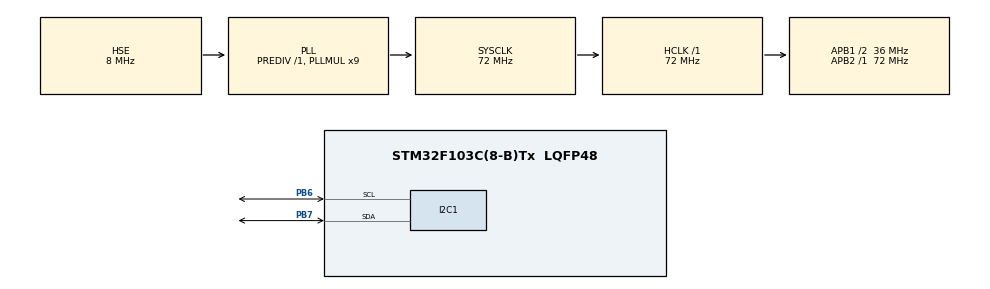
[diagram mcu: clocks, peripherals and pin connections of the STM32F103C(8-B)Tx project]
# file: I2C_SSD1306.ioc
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I2C1.I2C_Mode=I2C_Fast
Mcu.Family=STM32F1
Mcu.Name=STM32F103C(8-B)Tx
Mcu.Package=LQFP48
NVIC.PriorityGroup=NVIC_PRIORITYGROUP_4
PA13.Mode=Serial_Wire
PA13.Signal=SYS_JTMS-SWDIO
PA14.Mode=Serial_Wire
PA14.Signal=SYS_JTCK-SWCLK
PB6.Mode=I2C
PB6.Signal=I2C1_SCL
PB7.Mode=I2C
PB7.Signal=I2C1_SDA
PD0-OSC_IN.Mode=HSE-External-Oscillator
PD0-OSC_IN.Signal=RCC_OSC_IN
PD1-OSC_OUT.Mode=HSE-External-Oscillator
PD1-OSC_OUT.Signal=RCC_OSC_OUT
ProjectManager.HeapSize=0x200
ProjectManager.StackSize=0x400
ProjectManager.TargetToolchain=MDK-ARM V5.32
RCC.AHBFreq_Value=72000000
RCC.APB1CLKDivider=RCC_HCLK_DIV2
RCC.APB1Freq_Value=36000000
RCC.APB1TimFreq_Value=72000000
RCC.APB2Freq_Value=72000000
RCC.APB2TimFreq_Value=72000000
RCC.HCLKFreq_Value=72000000
RCC.PLLMUL=RCC_PLL_MUL9
RCC.PLLSourceVirtual=RCC_PLLSOURCE_HSE
RCC.SYSCLKFreq_VALUE=72000000
RCC.SYSCLKSource=RCC_SYSCLKSOURCE_PLLCLK
RCC.USBFreq_Value=72000000
board=custom

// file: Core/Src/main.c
/* USER CODE BEGIN Header */
/**
  ******************************************************************************
  * @file           : main.c
  * @brief          : Main program body
  ******************************************************************************
  * @attention
  *
  * Copyright (c) 2024 STMicroelectronics.
  * All rights reserved.
  *
  * This software is licensed under terms that can be found in the LICENSE file
  * in the root directory of this software component.
  * If no LICENSE file comes with this software, it is provided AS-IS.
  *
  ******************************************************************************
  */
/* USER CODE END Header */
#include "main.h"

/* USER CODE BEGIN Includes */
#include "fonts.h"
#include "ssd1306.h"
/* USER CODE END Includes */

I2C_HandleTypeDef hi2c1;

void SystemClock_Config(void);
static void MX_GPIO_Init(void);
static void MX_I2C1_Init(void);

/* USER CODE BEGIN 0 */
// 'icons8-calendar-22', 22x22px
const unsigned char epd_bitmap_icons8_calendar_22 [] = {
	0xf9, 0xfe, 0x7c, 0xf5, 0xfe, 0xbc, 0x84, 0x00, 0x84, 0x80, 0x00, 0x04, 0x80, 0x00, 0x04, 0x80,
	0x00, 0x04, 0xff, 0xff, 0xfc, 0x80, 0x00, 0x04, 0x80, 0x00, 0x04, 0x86, 0x49, 0x84, 0x86, 0xfd,
	0x84, 0x80, 0x00, 0x04, 0x82, 0x49, 0x04, 0x86, 0xfd, 0x84, 0x82, 0x49, 0x04, 0x82, 0x49, 0x04,
	0x86, 0xfd, 0x84, 0x82, 0x49, 0x04, 0x80, 0x00, 0x04, 0x80, 0x00, 0x04, 0x80, 0x00, 0x04, 0xff,
	0xff, 0xfc
};
// 'icons8-time-20', 20x20px
// 'icons8-time-20 (1)', 20x20px
const unsigned char epd_bitmap_icons8_time_20__1_ []= {
	0xff, 0xff, 0xf0, 0xff, 0xff, 0xf0, 0xff, 0x0f, 0xf0, 0xff, 0x9f, 0xf0, 0xfe, 0x07, 0xf0, 0xfc,
	0x01, 0xf0, 0xf8, 0x01, 0xf0, 0xf1, 0x00, 0xf0, 0xf1, 0x80, 0xf0, 0xe0, 0xc0, 0x70, 0xe0, 0x60,
	0x70, 0xe0, 0x20, 0x70, 0xf0, 0x00, 0xf0, 0xf0, 0x00, 0xf0, 0xf8, 0x01, 0xf0, 0xfc, 0x03, 0xf0,
	0xfe, 0x07, 0xf0, 0xff, 0xff, 0xf0, 0xff, 0xff, 0xf0, 0xff, 0xff, 0xf0
};
// 'icons8-high-temperatures-64', 64x64px
const unsigned char epd_bitmap_icons8_high_temperatures_64 []  = {
	0x00, 0x00, 0x00, 0x00, 0x00, 0x00, 0x00, 0x00, 0x00, 0x00, 0x00, 0x03, 0xc0, 0x00, 0x00, 0x00,
	0x00, 0x00, 0x00, 0x0f, 0xf0, 0x00, 0x00, 0x00, 0x00, 0x00, 0x00, 0x1f, 0xf8, 0x00, 0x00, 0x00,
	0x00, 0x00, 0x00, 0x1f, 0xf8, 0x00, 0x00, 0x00, 0x00, 0x00, 0x00, 0x3f, 0xfc, 0x00, 0x00, 0x00,
	0x00, 0x00, 0x00, 0x3e, 0x7c, 0x00, 0x00, 0x00, 0x00, 0x00, 0x00, 0x3c, 0x3c, 0x00, 0x00, 0x00,
	0x00, 0x00, 0x00, 0x3c, 0x3c, 0x00, 0x00, 0x00, 0x00, 0x00, 0x1f, 0xfc, 0x3f, 0xf8, 0x00, 0x00,
	0x00, 0x00, 0x1f, 0xfc, 0x3f, 0xf8, 0x00, 0x00, 0x00, 0x00, 0x00, 0x3c, 0x3c, 0x00, 0x00, 0x00,
	0x00, 0x00, 0x00, 0x3c, 0x3c, 0x00, 0x00, 0x00, 0x00, 0x00, 0x00, 0x3c, 0x3c, 0x00, 0x00, 0x00,
	0x00, 0x00, 0x00, 0x3c, 0x3c, 0x00, 0x00, 0x00, 0x00, 0x00, 0x07, 0xfc, 0x3f, 0xe0, 0x00, 0x00,
	0x00, 0x00, 0x07, 0xfc, 0x3f, 0xe0, 0x00, 0x00, 0x00, 0x00, 0x00, 0x3c, 0x3c, 0x00, 0x00, 0x00,
	0x00, 0x00, 0x00, 0x3c, 0x3c, 0x00, 0x00, 0x00, 0x00, 0x00, 0x00, 0x3c, 0x3c, 0x00, 0x00, 0x00,
	0x00, 0x00, 0x00, 0x3c, 0x3c, 0x00, 0x00, 0x00, 0x00, 0x00, 0x1f, 0xfc, 0x3f, 0xf8, 0x00, 0x00,
	0x00, 0x00, 0x1f, 0xfc, 0x3f, 0xf8, 0x00, 0x00, 0x00, 0x00, 0x00, 0x3c, 0x3c, 0x00, 0x00, 0x00,
	0x00, 0x00, 0x00, 0x3c, 0x3c, 0x00, 0x00, 0x00, 0x00, 0x00, 0x00, 0x3c, 0x3c, 0x00, 0x00, 0x00,
	0x00, 0x00, 0x00, 0x3c, 0x3c, 0x00, 0x00, 0x00, 0x00, 0x00, 0x07, 0xfc, 0x3f, 0xe0, 0x00, 0x00,
	0x00, 0x00, 0x07, 0xfc, 0x3f, 0xe0, 0x00, 0x00, 0x00, 0x00, 0x00, 0x3c, 0x3c, 0x00, 0x00, 0x00,
	0x00, 0x00, 0x00, 0x3c, 0x3c, 0x00, 0x00, 0x00, 0x00, 0x00, 0x00, 0x3c, 0x3c, 0x00, 0x00, 0x00,
	0x00, 0x00, 0x00, 0x3c, 0x3c, 0x00, 0x00, 0x00, 0x00, 0x00, 0x1f, 0xfc, 0x3f, 0xf8, 0x00, 0x00,
	0x00, 0x00, 0x1f, 0xfc, 0x3f, 0xf8, 0x00, 0x00, 0x00, 0x00, 0x00, 0x3c, 0x3c, 0x00, 0x00, 0x00,
	0x00, 0x00, 0x00, 0x3c, 0x3c, 0x00, 0x00, 0x00, 0x00, 0x00, 0x00, 0x3c, 0x3c, 0x00, 0x00, 0x00,
	0x00, 0x00, 0x00, 0x3c, 0x3c, 0x00, 0x00, 0x00, 0x00, 0x00, 0x07, 0xfc, 0x3f, 0xe0, 0x00, 0x00,
	0x00, 0x00, 0x07, 0xfc, 0x3f, 0xe0, 0x00, 0x00, 0x00, 0x00, 0x00, 0x3c, 0x3c, 0x00, 0x00, 0x00,
	0x00, 0x00, 0x00, 0x3c, 0x3c, 0x00, 0x00, 0x00, 0x00, 0x00, 0x00, 0x3c, 0x3c, 0x00, 0x00, 0x00,
	0x00, 0x00, 0x00, 0x3c, 0x3c, 0x00, 0x00, 0x00, 0x00, 0x00, 0x00, 0x7c, 0x3e, 0x00, 0x00, 0x00,
	0x00, 0x00, 0x00, 0xfc, 0x3f, 0x00, 0x00, 0x00, 0x00, 0x00, 0x00, 0xfc, 0x3f, 0x00, 0x00, 0x00,
	0x00, 0x30, 0x01, 0xfc, 0x3f, 0x80, 0x00, 0x00, 0x00, 0x30, 0x01, 0xf8, 0x1f, 0x80, 0x00, 0x00,
	0x00, 0x30, 0x03, 0xf0, 0x0f, 0xc0, 0x00, 0x00, 0x00, 0x30, 0x03, 0xe0, 0x07, 0xc0, 0x00, 0x00,
	0x03, 0xff, 0x03, 0xe0, 0x07, 0xc0, 0xff, 0xc0, 0x03, 0xff, 0x03, 0xe0, 0x07, 0xc0, 0xff, 0xc0,
	0x00, 0x30, 0x03, 0xe0, 0x07, 0xc0, 0x00, 0x00, 0x00, 0x30, 0x03, 0xf0, 0x0f, 0xc0, 0x00, 0x00,
	0x00, 0x30, 0x01, 0xf8, 0x1f, 0x80, 0x00, 0x00, 0x00, 0x30, 0x01, 0xfc, 0x3f, 0x80, 0x00, 0x00,
	0x00, 0x00, 0x00, 0xff, 0xff, 0x00, 0x00, 0x00, 0x00, 0x00, 0x00, 0xff, 0xff, 0x00, 0x00, 0x00,
	0x00, 0x00, 0x00, 0x7f, 0xfe, 0x00, 0x00, 0x00, 0x00, 0x00, 0x00, 0x1f, 0xf8, 0x00, 0x00, 0x00,
	0x00, 0x00, 0x00, 0x07, 0xe0, 0x00, 0x00, 0x00, 0x00, 0x00, 0x00, 0x00, 0x00, 0x00, 0x00, 0x00
};
// 'icons8-high-temperatures-20', 20x20px
const unsigned char epd_bitmap_icons8_high_temperatures_20 [] = {
	0x00, 0x60, 0x00, 0x00, 0xf0, 0x00, 0x00, 0x90, 0x00, 0x00, 0x90, 0x00, 0x00, 0x90, 0x00, 0x00,
	0x90, 0x00, 0x00, 0x90, 0x00, 0x00, 0x90, 0x00, 0x01, 0x98, 0x00, 0x00, 0x90, 0x00, 0x03, 0x9c,
	0x00, 0x00, 0x90, 0x00, 0x01, 0x98, 0x00, 0x00, 0x90, 0x00, 0x00, 0x90, 0x00, 0x11, 0x98, 0x00,
	0x39, 0x09, 0xc0, 0x11, 0x98, 0x00, 0x00, 0xf0, 0x00, 0x00, 0x60, 0x00
};

/* USER CODE END 0 */

int main(void)
{

  /* MCU Configuration--------------------------------------------------------*/

  /* Reset of all peripherals, Initializes the Flash interface and the Systick. */
  HAL_Init();

  /* Configure the system clock */
  SystemClock_Config();

  /* Initialize all configured peripherals */
  MX_GPIO_Init();
  MX_I2C1_Init();
  /* USER CODE BEGIN 2 */
	SSD1306_Init();
	SSD1306_DrawBitmap(0,0,epd_bitmap_icons8_high_temperatures_20,20,20,1);
	//SSD1306_DrawBitmap(0,24,epd_bitmap_icons8_time_20__1_ ,20,20,1);
  SSD1306_GotoXY (24,2);
  SSD1306_Puts ("5", &Font_7x10, 1);
//  SSD1306_GotoXY (0, 30);
//  SSD1306_Puts ("pham", &Font_16x26, 1);
  SSD1306_UpdateScreen();
  //HAL_Delay (1000);

//  SSD1306_ScrollRight(0,7);
//  HAL_Delay(3000);
//  SSD1306_ScrollLeft(0,7);
//  HAL_Delay(3000);
//  SSD1306_Stopscroll();
//  SSD1306_Clear();
//  SSD1306_GotoXY (35,0);
//  SSD1306_Puts ("SCORE", &Font_11x18, 1);
  /* USER CODE END 2 */

  /* Infinite loop */
  while (1)
  {

    /* USER CODE BEGIN 3 */
//	for ( int x = 1; x <= 10000 ; x++ )
//	{
//		itoa(x, snum, 10);
//		SSD1306_GotoXY (0, 30);
//		SSD1306_Puts ("             ", &Font_16x26, 1);
//		SSD1306_UpdateScreen();
//		if(x < 10) {
//			SSD1306_GotoXY (53, 30);  // 1 DIGIT
//		}
//		else if (x < 100 ) {
//			SSD1306_GotoXY (45, 30);  // 2 DIGITS
//		}
//		else if (x < 1000 ) {
//			SSD1306_GotoXY (37, 30);  // 3 DIGITS
//		}
//		else {
//			SSD1306_GotoXY (30, 30);  // 4 DIGIS
//		}
//		SSD1306_Puts (snum, &Font_16x26, 1);
//		SSD1306_UpdateScreen();
//		HAL_Delay (500);
//	    }
	}
  /* USER CODE END 3 */
}

void SystemClock_Config(void)
{
  RCC_OscInitTypeDef RCC_OscInitStruct = {0};
  RCC_ClkInitTypeDef RCC_ClkInitStruct = {0};

  /** Initializes the RCC Oscillators according to the specified parameters
  * in the RCC_OscInitTypeDef structure.
  */
  RCC_OscInitStruct.OscillatorType = RCC_OSCILLATORTYPE_HSE;
  RCC_OscInitStruct.HSEState = RCC_HSE_ON;
  RCC_OscInitStruct.HSEPredivValue = RCC_HSE_PREDIV_DIV1;
  RCC_OscInitStruct.HSIState = RCC_HSI_ON;
  RCC_OscInitStruct.PLL.PLLState = RCC_PLL_ON;
  RCC_OscInitStruct.PLL.PLLSource = RCC_PLLSOURCE_HSE;
  RCC_OscInitStruct.PLL.PLLMUL = RCC_PLL_MUL9;
  if (HAL_RCC_OscConfig(&RCC_OscInitStruct) != HAL_OK)
  {
    Error_Handler();
  }

  /** Initializes the CPU, AHB and APB buses clocks
  */
  RCC_ClkInitStruct.ClockType = RCC_CLOCKTYPE_HCLK|RCC_CLOCKTYPE_SYSCLK
                              |RCC_CLOCKTYPE_PCLK1|RCC_CLOCKTYPE_PCLK2;
  RCC_ClkInitStruct.SYSCLKSource = RCC_SYSCLKSOURCE_PLLCLK;
  RCC_ClkInitStruct.AHBCLKDivider = RCC_SYSCLK_DIV1;
  RCC_ClkInitStruct.APB1CLKDivider = RCC_HCLK_DIV2;
  RCC_ClkInitStruct.APB2CLKDivider = RCC_HCLK_DIV1;

  if (HAL_RCC_ClockConfig(&RCC_ClkInitStruct, FLASH_LATENCY_2) != HAL_OK)
  {
    Error_Handler();
  }
}

static void MX_I2C1_Init(void)
{

  hi2c1.Instance = I2C1;
  hi2c1.Init.ClockSpeed = 400000;
  hi2c1.Init.DutyCycle = I2C_DUTYCYCLE_2;
  hi2c1.Init.OwnAddress1 = 0;
  hi2c1.Init.AddressingMode = I2C_ADDRESSINGMODE_7BIT;
  hi2c1.Init.DualAddressMode = I2C_DUALADDRESS_DISABLE;
  hi2c1.Init.OwnAddress2 = 0;
  hi2c1.Init.GeneralCallMode = I2C_GENERALCALL_DISABLE;
  hi2c1.Init.NoStretchMode = I2C_NOSTRETCH_DISABLE;
  if (HAL_I2C_Init(&hi2c1) != HAL_OK)
  {
    Error_Handler();
  }

}

static void MX_GPIO_Init(void)
{

  /* GPIO Ports Clock Enable */
  __HAL_RCC_GPIOD_CLK_ENABLE();
  __HAL_RCC_GPIOA_CLK_ENABLE();
  __HAL_RCC_GPIOB_CLK_ENABLE();

}

void Error_Handler(void)
{
  __disable_irq();
  while (1)
  {
  }
}
